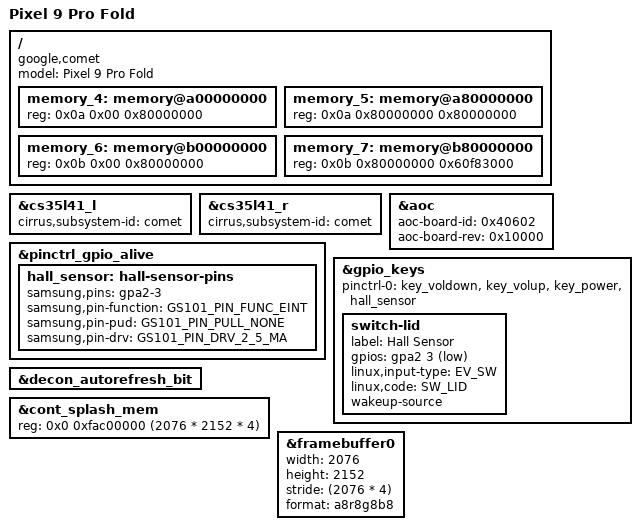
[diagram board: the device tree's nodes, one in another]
// SPDX-License-Identifier: GPL-2.0-only
/*
 * Pixel 9 Pro Fold (comet) Device Tree
 *
 * Copyright 2025 Trijal Saha - <trijalsaha2012@gmail.com>
 */

/dts-v1/;

#include "zumapro-pixel-common.dtsi"
#include "zumapro-caimito-bcm4390.dtsi"
#include "zumapro-caimito-s5400.dtsi"
#include "zumapro-caimito-cs35l41.dtsi"

/ {
	model = "Pixel 9 Pro Fold";
	compatible = "google,comet", "google,zumapro-comet", "google,zumapro";

	memory_4: memory@a00000000 {
		device_type = "memory";
		reg = <0x0a 0x00 0x80000000>;
	};

	memory_5: memory@a80000000 {
		device_type = "memory";
		reg = <0x0a 0x80000000 0x80000000>;
	};

	memory_6: memory@b00000000 {
		device_type = "memory";
		reg = <0x0b 0x00 0x80000000>;
	};

	memory_7: memory@b80000000 {
		device_type = "memory";
		reg = <0x0b 0x80000000 0x60f83000>;
	};
};

/* Board identity the AOC firmware reads at boot. */
/*
 * The Halo DSP speaker-protection tuning is specific to this board's drivers
 * and to each channel, so the firmware has to be named for both.  This is what
 * wm_adsp interpolates as the system name: the amplifiers ask for
 * cirrus/cs35l41-dsp1-spk-prot-comet.wmfw, and for a tuning of the same stem
 * with "-r" appended on the right-hand amplifier, which carries the prefix.
 */
&cs35l41_l {
	cirrus,subsystem-id = "comet";
};

&cs35l41_r {
	cirrus,subsystem-id = "comet";
};

&aoc {
	aoc-board-id = <0x40602>;
	aoc-board-rev = <0x10000>;
};

/*
 * The fold sensor: a DRV5032 Hall-effect switch on gpa2-3, which closes as the
 * halves come together. It needs no driver of its own - it is one GPIO whose
 * state is a lid switch, which is what gpio-keys reports natively.
 *
 * Active low, because the vendor driver inverted the level it read. Note that
 * the vendor node also carries interrupts = <4 0>, naming a different pin to
 * its own hall,gpio = <&gpa2 3>; nothing ever read it, since that driver took
 * the interrupt from gpio_to_irq() on the GPIO. gpa2-3 is the pin.
 */
&pinctrl_gpio_alive {
	hall_sensor: hall-sensor-pins {
		samsung,pins = "gpa2-3";
		samsung,pin-function = <GS101_PIN_FUNC_EINT>;
		samsung,pin-pud = <GS101_PIN_PULL_NONE>;
		samsung,pin-drv = <GS101_PIN_DRV_2_5_MA>;
	};
};

&gpio_keys {
	pinctrl-0 = <&key_voldown>, <&key_volup>, <&key_power>, <&hall_sensor>;

	switch-lid {
		label = "Hall Sensor";
		gpios = <&gpa2 3 GPIO_ACTIVE_LOW>;
		linux,input-type = <EV_SW>;
		linux,code = <SW_LID>;
		wakeup-source;
	};
};

&decon_autorefresh_bit {
	status = "okay";
};

&cont_splash_mem {
	// reg = <0x0 0xfac00000 (1440 * 3120 * 4)>;
	reg = <0x0 0xfac00000 (2076 * 2152 * 4)>;

	status = "okay";
};

&framebuffer0 {
	// width = <1440>;
	// height = <3120>;
	// stride = <(1440 * 4)>;
	width = <2076>;
	height = <2152>;
	stride = <(2076 * 4)>;
	format = "a8r8g8b8";

	status = "okay";
};
